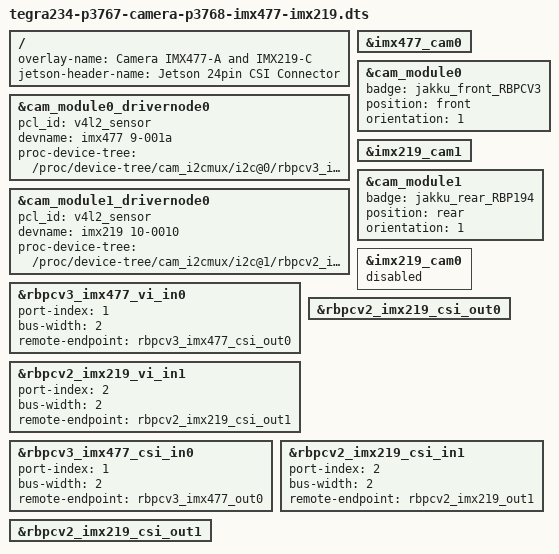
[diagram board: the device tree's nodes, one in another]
// SPDX-License-Identifier: GPL-2.0-only
/*
 * Jetson Device-tree overlay to enable Camera IMX477 rbpcv3 on portA along with
 * camera IMX219 on portB, for dual cam connector baseboards
 *
 * Copyright (c) 2022-2023 NVIDIA CORPORATION. All rights reserved.
 *
 */

/dts-v1/;
/plugin/;

#include <dt-common/jetson/tegra234-p3767-0000-common.h>

/ {
	overlay-name = "Camera IMX477-A and IMX219-C";
	jetson-header-name = "Jetson 24pin CSI Connector";
        compatible = JETSON_COMPATIBLE_P3768;

	/* IMX77 sensor module on CSI PORT A and IMX219 sensor module on CSI PORT B  */
	fragment@0 {
		target = <&imx477_cam0>;
		__overlay__ {
			status = "okay";
		};
	};
	fragment@1 {
		target = <&cam_module0>;
		__overlay__ {
			status = "okay";
			badge = "jakku_front_RBPCV3";
			position = "front";
			orientation = "1";
		};
	};
	fragment@2 {
		target = <&cam_module0_drivernode0>;
		__overlay__ {
			status = "okay";
			pcl_id = "v4l2_sensor";
			devname = "imx477 9-001a";
			proc-device-tree = "/proc/device-tree/cam_i2cmux/i2c@0/rbpcv3_imx477_a@1a";
		};
	};
	fragment@3 {
		target = <&imx219_cam1>;
		__overlay__ {
			status = "okay";
		};
	};
	fragment@4 {
		target = <&cam_module1>;
		__overlay__ {
			status = "okay";
			badge = "jakku_rear_RBP194";
			position = "rear";
			orientation = "1";
		};
	};
	fragment@5 {
		target = <&cam_module1_drivernode0>;
		__overlay__ {
			status = "okay";
			pcl_id = "v4l2_sensor";
			devname = "imx219 10-0010";
			proc-device-tree = "/proc/device-tree/cam_i2cmux/i2c@1/rbpcv2_imx219_c@10";
		};
	};
	fragment@6 {
		target = <&imx219_cam0>;
		__overlay__ {
			status = "disabled";
		};
	};
	fragment@7 {
		target = <&rbpcv3_imx477_vi_in0>;
		__overlay__ {
			status = "okay";
			port-index = <1>;
			bus-width = <2>;
			remote-endpoint = <&rbpcv3_imx477_csi_out0>;
		};
	};
	fragment@8 {
		target = <&rbpcv2_imx219_vi_in1>;
		__overlay__ {
			status = "okay";
			port-index = <2>;
			bus-width = <2>;
			remote-endpoint = <&rbpcv2_imx219_csi_out1>;
		};
	};
	fragment@9 {
		target = <&rbpcv3_imx477_csi_in0>;
		__overlay__ {
			status = "okay";
			port-index = <1>;
			bus-width = <2>;
			remote-endpoint = <&rbpcv3_imx477_out0>;
		};
	};
	fragment@10 {
		target = <&rbpcv2_imx219_csi_out0>;
		__overlay__ {
			status = "okay";
		};
	};
	fragment@11 {
		target = <&rbpcv2_imx219_csi_in1>;
		__overlay__ {
			status = "okay";
			port-index = <2>;
			bus-width = <2>;
			remote-endpoint = <&rbpcv2_imx219_out1>;
		};
	};
	fragment@12 {
		target = <&rbpcv2_imx219_csi_out1>;
		__overlay__ {
			status = "okay";
		};
	};
};
